# STM32MP153 register map
File version: 1.3
CPU: CM4 r0p1, little endian, no MPU, FPU, 4 interrupt priority bits
Registers are 32-bit, read-write, reset 0x0 unless marked. A register's access mark holds for its fields unless they carry their own. Offsets are from the block's base; [hi:lo] are bit positions; {n}, {i} and the like mark numbered series.

## DDRPERFM
Base 0x5A007000
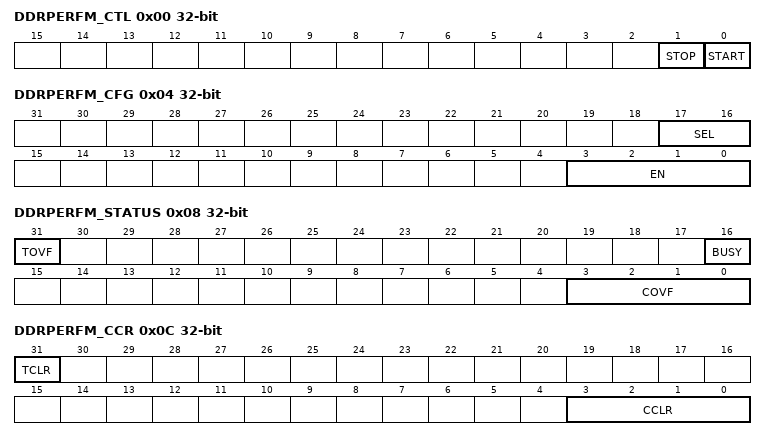
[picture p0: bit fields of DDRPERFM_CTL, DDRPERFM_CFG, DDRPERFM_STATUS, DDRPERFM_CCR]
0x00 DDRPERFM_CTL wo — Write-only register. A read request returns all zeros.
  [1] STOP, [0] START
0x04 DDRPERFM_CFG — DDRPERFM configurationl register
  [17:16] SEL, [3:0] EN
0x08 DDRPERFM_STATUS ro
  [31] TOVF, [16] BUSY, [3:0] COVF
0x0C DDRPERFM_CCR wo — Write-only register. A read request returns all zeros
  [31] TCLR, [3:0] CCLR
0x10 DDRPERFM_IER — DDRPERFM interrupt enable register
  [0] OVFIE
0x14 DDRPERFM_ISR ro — DDRPERFM interrupt status register
  [0] OVFF
0x18 DDRPERFM_ICR wo — Write-only register. A read request returns all zeros
  [0] OVF
0x20 DDRPERFM_TCNT ro — DDRPERFM time counter register
  [31:0] CNT
{0x60+8i} DDRPERFM_CNT{i} ro (i=0..3) — DDRPERFM event counter {i} register
  [31:0] CNT
0x3F0 DDRPERFM_HWCFG ro reset 0x4 — DDRPERFM hardware configuration register
  [3:0] NCNT
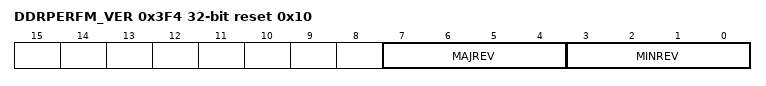
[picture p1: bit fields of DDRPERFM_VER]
0x3F4 DDRPERFM_VER ro reset 0x10 — DDRPERFM version register
  [7:4] MAJREV, [3:0] MINREV
0x3F8 DDRPERFM_ID ro reset 0x140061
0x3FC DDRPERFM_SID ro reset 0xA3C5DD01 — DDRPERFM magic ID register

## DLYBQS
Base 0x58004000
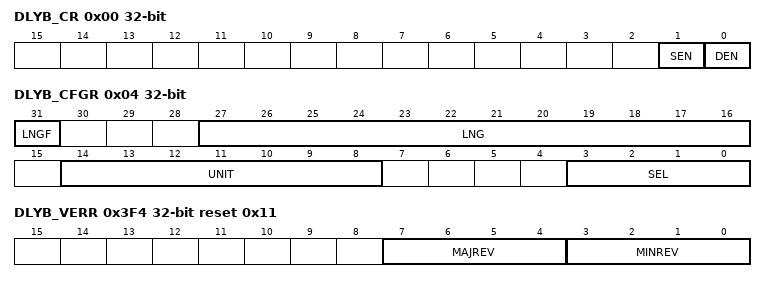
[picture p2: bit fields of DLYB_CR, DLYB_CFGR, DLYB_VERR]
0x00 DLYB_CR — DLYB control register
  [1] SEN, [0] DEN
0x04 DLYB_CFGR — DLYB configuration register
  [31] LNGF ro, [27:16] LNG ro, [14:8] UNIT, [3:0] SEL
0x3F4 DLYB_VERR ro reset 0x11 — DLYB IP version register
  [7:4] MAJREV, [3:0] MINREV
0x3F8 DLYB_IPIDR ro reset 0x140051 — DLYB IP identification register
  [31:0] ID
0x3FC DLYB_SIDR ro reset 0xA3C5DD01 — DLYB size ID register
  [31:0] SID

## DLYBSD1
Base 0x58006000
Same registers: DLYBSD3 0x48005000, DLYBSD2 0x58008000
Registers as DLYBQS; these are added or differ:
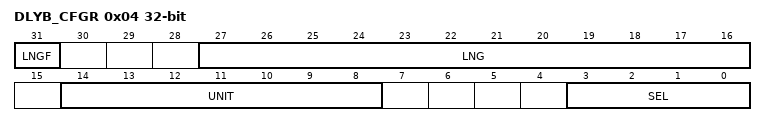
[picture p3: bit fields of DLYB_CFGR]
0x04 DLYB_CFGR access per field — DLYB configuration register
  [31] LNGF ro, [27:16] LNG ro, [14:8] UNIT rw, [3:0] SEL rw

## DMA1
Base 0x48000000
Same registers: DMA2 0x48001000
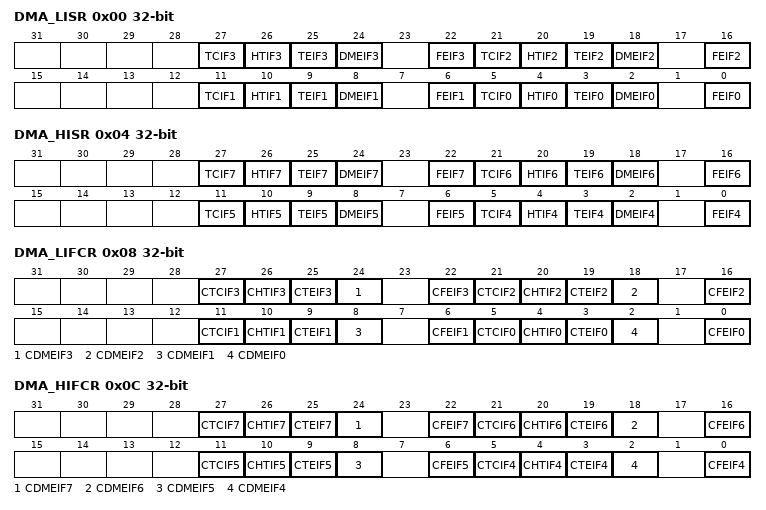
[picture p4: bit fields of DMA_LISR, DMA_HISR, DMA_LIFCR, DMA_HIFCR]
0x00 DMA_LISR ro — DMA low interrupt status register
  [27] TCIF3, [26] HTIF3, [25] TEIF3, [24] DMEIF3, [22] FEIF3, [21] TCIF2, [20] HTIF2, [19] TEIF2, [18] DMEIF2, [16] FEIF2, [11] TCIF1, [10] HTIF1, [9] TEIF1, [8] DMEIF1, [6] FEIF1, [5] TCIF0, [4] HTIF0, [3] TEIF0, [2] DMEIF0, [0] FEIF0
0x04 DMA_HISR ro — DMA high interrupt status register
  [27] TCIF7, [26] HTIF7, [25] TEIF7, [24] DMEIF7, [22] FEIF7, [21] TCIF6, [20] HTIF6, [19] TEIF6, [18] DMEIF6, [16] FEIF6, [11] TCIF5, [10] HTIF5, [9] TEIF5, [8] DMEIF5, [6] FEIF5, [5] TCIF4, [4] HTIF4, [3] TEIF4, [2] DMEIF4, [0] FEIF4
0x08 DMA_LIFCR wo — DMA low interrupt flag clear register
  [27] CTCIF3, [26] CHTIF3, [25] CTEIF3, [24] CDMEIF3, [22] CFEIF3, [21] CTCIF2, [20] CHTIF2, [19] CTEIF2, [18] CDMEIF2, [16] CFEIF2, [11] CTCIF1, [10] CHTIF1, [9] CTEIF1, [8] CDMEIF1, [6] CFEIF1, [5] CTCIF0, [4] CHTIF0, [3] CTEIF0, [2] CDMEIF0, [0] CFEIF0
0x0C DMA_HIFCR wo — DMA high interrupt flag clear register
  [27] CTCIF7, [26] CHTIF7, [25] CTEIF7, [24] CDMEIF7, [22] CFEIF7, [21] CTCIF6, [20] CHTIF6, [19] CTEIF6, [18] CDMEIF6, [16] CFEIF6, [11] CTCIF5, [10] CHTIF5, [9] CTEIF5, [8] CDMEIF5, [6] CFEIF5, [5] CTCIF4, [4] CHTIF4, [3] CTEIF4, [2] CDMEIF4, [0] CFEIF4
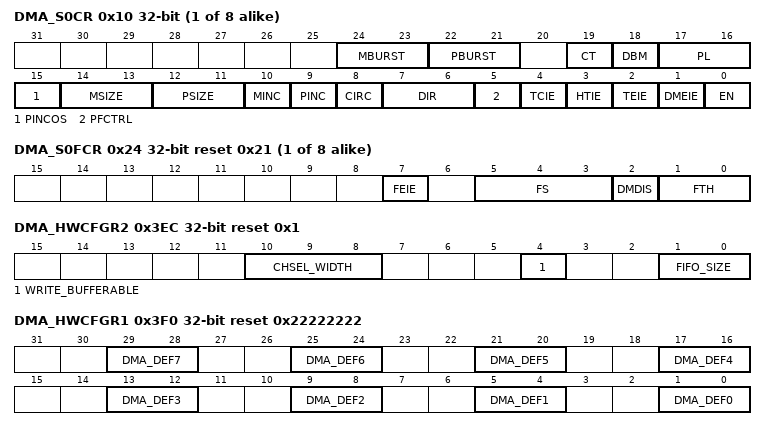
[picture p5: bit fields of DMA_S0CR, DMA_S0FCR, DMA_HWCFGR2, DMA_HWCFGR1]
{0x10+0x18*i} DMA_S{i}CR (i=0..7) — This register is used to configure the concerned stream.
  [24:23] MBURST, [22:21] PBURST, [19] CT, [18] DBM, [17:16] PL, [15] PINCOS, [14:13] MSIZE, [12:11] PSIZE, [10] MINC, [9] PINC, [8] CIRC, [7:6] DIR, [5] PFCTRL, [4] TCIE, [3] HTIE, [2] TEIE, [1] DMEIE, [0] EN
{0x14+0x18*i} DMA_S{i}NDTR (i=0..7) — DMA stream {i} number of data register
  [15:0] NDT
{0x18+0x18*i} DMA_S{i}PAR (i=0..7) — DMA stream {i} peripheral address register
  [31:0] PAR
{0x1C+0x18*i} DMA_S{i}M0AR (i=0..7) — DMA stream {i} memory 0 address register
  [31:0] M0A
{0x20+0x18*i} DMA_S{i}M1AR (i=0..7) — DMA stream {i} memory 1 address register
  [31:0] M1A
{0x24+0x18*i} DMA_S{i}FCR access per field reset 0x21 (i=0..7) — DMA stream {i} FIFO control register
  [7] FEIE rw, [5:3] FS ro, [2] DMDIS rw, [1:0] FTH rw
0x3EC DMA_HWCFGR2 ro reset 0x1 — DMA hardware configuration 2register
  [10:8] CHSEL_WIDTH, [4] WRITE_BUFFERABLE, [1:0] FIFO_SIZE
0x3F0 DMA_HWCFGR1 ro reset 0x22222222 — DMA hardware configuration 1 register
  [4n+1:4n] DMA_DEF{n} (n=0..7)
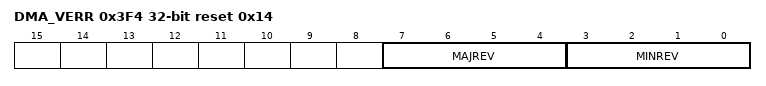
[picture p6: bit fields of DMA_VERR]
0x3F4 DMA_VERR ro reset 0x14 — This register identifies the version of the IP.
  [7:4] MAJREV, [3:0] MINREV
0x3F8 DMA_IPDR ro reset 0x100002 — DMA IP identification register
  [31:0] ID
0x3FC DMA_SIDR ro reset 0xA3C5DD01 — DMA size identification register
  [31:0] SID
